VERSION "OAS derived read-only subset"

NS_ :

BS_:

BU_: BCM CLU ESC LVR MDPS

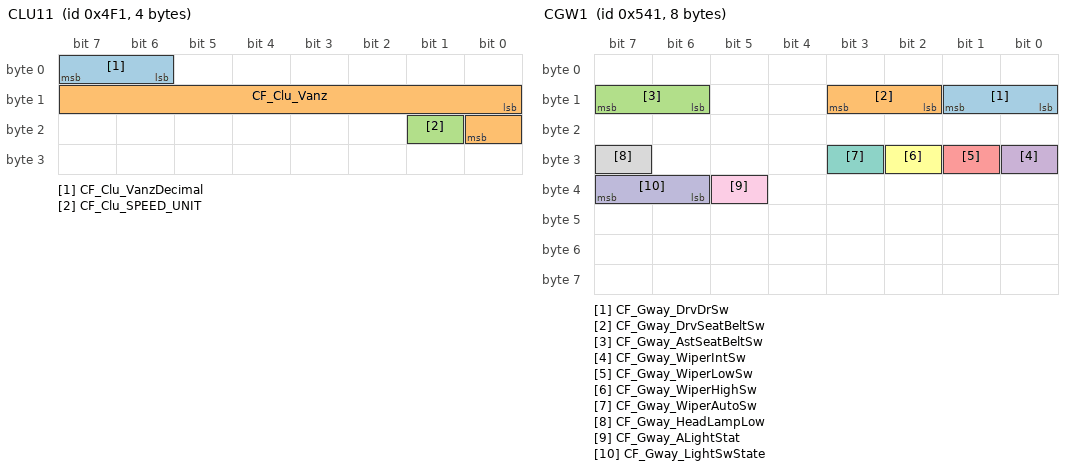
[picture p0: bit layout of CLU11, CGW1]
BO_ 1265 CLU11: 4 CLU
 SG_ CF_Clu_VanzDecimal : 6|2@1+ (0.125,0.0) [0.0|0.375] "" EMS
 SG_ CF_Clu_Vanz : 8|9@1+ (0.5,0.0) [0.0|255.5] "km/h or MPH" BCM
 SG_ CF_Clu_SPEED_UNIT : 17|1@1+ (1.0,0.0) [0.0|1.0] "" BCM

BO_ 688 SAS11: 5 MDPS
 SG_ SAS_Angle : 0|16@1- (0.1,0.0) [-3276.8|3276.7] "Deg" CLU

BO_ 916 TCS13: 8 ESC
 SG_ ACCEL_REF_ACC : 32|11@1+ (0.01,-10.23) [-10.23|10.24] "m/s^2" EMS
 SG_ DriverOverride : 45|2@1+ (1.0,0.0) [0.0|3.0] "" CLU

BO_ 1345 CGW1: 8 BCM
 SG_ CF_Gway_DrvDrSw : 8|2@1+ (1.0,0.0) [0.0|3.0] "" CLU
 SG_ CF_Gway_DrvSeatBeltSw : 10|2@1+ (1.0,0.0) [0.0|3.0] "" CLU
 SG_ CF_Gway_AstSeatBeltSw : 14|2@1+ (1.0,0.0) [0.0|3.0] "" CLU
 SG_ CF_Gway_WiperIntSw : 24|1@1+ (1.0,0.0) [0.0|1.0] "" CLU
 SG_ CF_Gway_WiperLowSw : 25|1@1+ (1.0,0.0) [0.0|1.0] "" CLU
 SG_ CF_Gway_WiperHighSw : 26|1@1+ (1.0,0.0) [0.0|1.0] "" CLU
 SG_ CF_Gway_WiperAutoSw : 27|1@1+ (1.0,0.0) [0.0|1.0] "" CLU
 SG_ CF_Gway_HeadLampLow : 31|1@1+ (1.0,0.0) [0.0|1.0] "" CLU
 SG_ CF_Gway_ALightStat : 37|1@1+ (1.0,0.0) [0.0|1.0] "" CLU
 SG_ CF_Gway_LightSwState : 38|2@1+ (1.0,0.0) [0.0|3.0] "" CLU

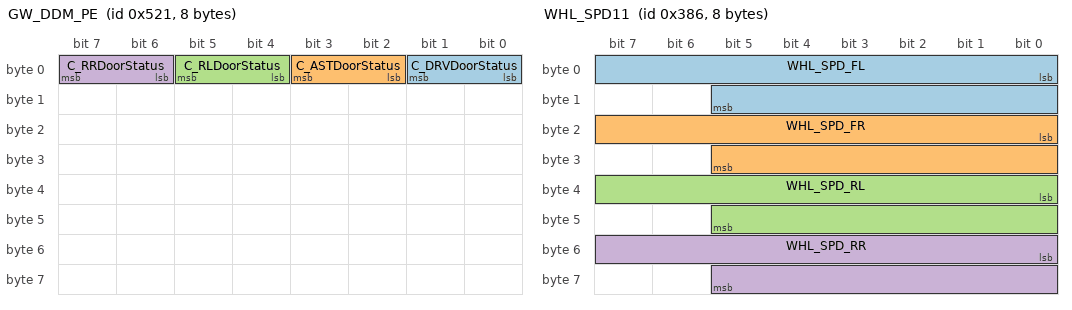
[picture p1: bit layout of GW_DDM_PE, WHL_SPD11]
BO_ 1313 GW_DDM_PE: 8 BCM
 SG_ C_DRVDoorStatus : 0|2@1+ (1.0,0.0) [0.0|3.0] "" CLU
 SG_ C_ASTDoorStatus : 2|2@1+ (1.0,0.0) [0.0|3.0] "" CLU
 SG_ C_RLDoorStatus : 4|2@1+ (1.0,0.0) [0.0|3.0] "" CLU
 SG_ C_RRDoorStatus : 6|2@1+ (1.0,0.0) [0.0|3.0] "" CLU

BO_ 66 DATC12: 8 DATC
 SG_ CR_Datc_DrTempDispC : 0|8@1+ (0.5,14.0) [15.0|32.0] "deg" CLU
 SG_ CR_Datc_PsTempDispC : 16|8@1+ (0.5,14.0) [15.0|32.0] "deg" CLU

BO_ 871 LVR12: 8 LVR
 SG_ CF_Lvr_Gear : 32|4@1+ (1.0,0.0) [0.0|15.0] "" CLU

BO_ 902 WHL_SPD11: 8 ABS
 SG_ WHL_SPD_FL : 0|14@1+ (0.03125,0.0) [0.0|511.96875] "km/h" CLU
 SG_ WHL_SPD_FR : 16|14@1+ (0.03125,0.0) [0.0|511.96875] "km/h" CLU
 SG_ WHL_SPD_RL : 32|14@1+ (0.03125,0.0) [0.0|511.96875] "km/h" CLU
 SG_ WHL_SPD_RR : 48|14@1+ (0.03125,0.0) [0.0|511.96875] "km/h" CLU

BO_ 905 SCC14: 8 SCC
 SG_ ACCMode : 32|3@1+ (1.0,0.0) [0.0|7.0] "" CLU

VAL_ 871 CF_Lvr_Gear 12 "T" 5 "D" 8 "S" 6 "N" 7 "R" 0 "P";
VAL_ 905 ACCMode 0 "off" 1 "enabled" 2 "driver_override" 3 "off_maybe_fault" 4 "cancelled";
